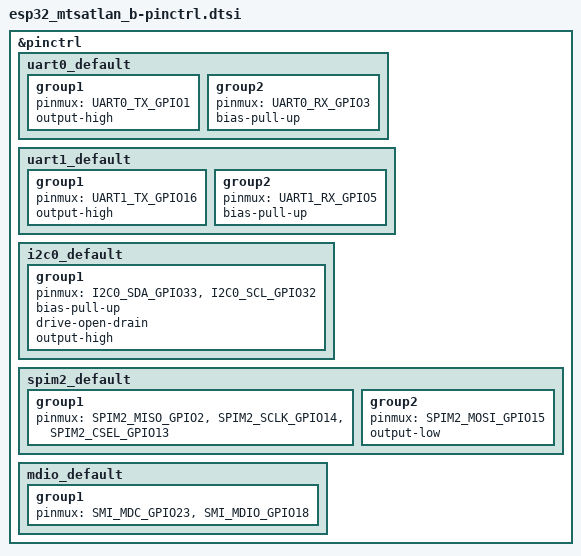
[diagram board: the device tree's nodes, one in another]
/*
 * Copyright (c) 2022 Grant Ramsay <grant.ramsay@hotmail.com>
 *
 * SPDX-License-Identifier: Apache-2.0
 */

#include <zephyr/dt-bindings/pinctrl/esp-pinctrl-common.h>
#include <dt-bindings/pinctrl/esp32-pinctrl.h>
#include <zephyr/dt-bindings/pinctrl/esp32-gpio-sigmap.h>

&pinctrl {

	uart0_default: uart0_default {
		group1 {
			pinmux = <UART0_TX_GPIO1>;
			output-high;
		};
		group2 {
			pinmux = <UART0_RX_GPIO3>;
			bias-pull-up;
		};
	};

	uart1_default: uart1_default {
		group1 {
			pinmux = <UART1_TX_GPIO16>;
			output-high;
		};
		group2 {
			pinmux = <UART1_RX_GPIO5>;
			bias-pull-up;
		};
	};

  i2c0_default: i2c0_default {
		group1 {
			pinmux = 
        <I2C0_SDA_GPIO33>,
				<I2C0_SCL_GPIO32>;
			bias-pull-up;
			drive-open-drain;
			output-high;
		};
	};

  spim2_default: spim2_default {
		group1 {
			pinmux = 
        <SPIM2_MISO_GPIO2>,
        <SPIM2_SCLK_GPIO14>,
        <SPIM2_CSEL_GPIO13>;
};
		group2 {
			pinmux = <SPIM2_MOSI_GPIO15>;
			output-low;
		};
	};

	mdio_default: mdio_default {
		group1 {
			pinmux = 
        <SMI_MDC_GPIO23>,
				<SMI_MDIO_GPIO18>;
		};
	};

};
